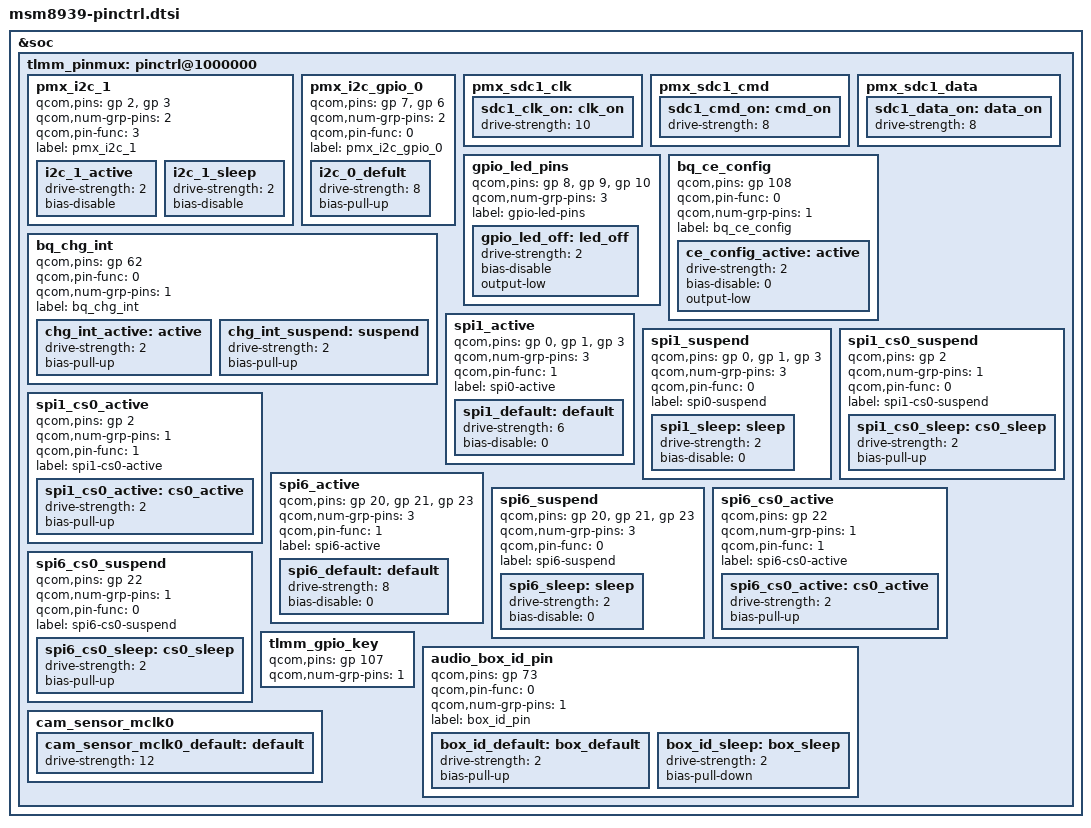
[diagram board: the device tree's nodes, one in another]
/* Copyright (c) 2014, The Linux Foundation. All rights reserved.
 *
 * This program is free software; you can redistribute it and/or modify
 * it under the terms of the GNU General Public License version 2 and
 * only version 2 as published by the Free Software Foundation.
 *
 * This program is distributed in the hope that it will be useful,
 * but WITHOUT ANY WARRANTY; without even the implied warranty of
 * MERCHANTABILITY or FITNESS FOR A PARTICULAR PURPOSE.  See the
 * GNU General Public License for more details.
 */

#include "../msm8939-pinctrl.dtsi"

&soc {
	tlmm_pinmux: pinctrl@1000000 {
		pmx_i2c_1 {
			qcom,pins = <&gp 2>, <&gp 3>; /* SDA, SCL */
			qcom,num-grp-pins = <2>;
			qcom,pin-func = <3>;
			label = "pmx_i2c_1";

			i2c_1_active: i2c_1_active {
				drive-strength = <2>;
				bias-disable;
			};

			i2c_1_sleep: i2c_1_sleep {
				drive-strength = <2>;
				bias-disable;
			};
		};

		pmx_i2c_gpio_0{
			/* CLK, DATA */
			qcom,pins = <&gp 7>, <&gp 6>;
			qcom,num-grp-pins = <2>;
			qcom,pin-func = <0>;
			label = "pmx_i2c_gpio_0";
			i2c_0_defult: i2c_0_defult {
				drive-strength = <8>; /* 8 MA */
				bias-pull-up; /* pull up */
			};
		};

		/delete-node/ sdhc2_cd_pin;

		pmx_sdc1_clk {
			sdc1_clk_on: clk_on {
				drive-strength = <10>; /* 10 MA */
			};
		};

		pmx_sdc1_cmd {
			sdc1_cmd_on: cmd_on {
				drive-strength = <8>; /* 8 MA */
			};
		};

		pmx_sdc1_data {
			sdc1_data_on: data_on {
				drive-strength = <8>; /* 8 MA */
			};
		};

		gpio_led_pins {
			qcom,pins = <&gp 8>, <&gp 9>, <&gp 10>;
			qcom,num-grp-pins = <3>;
			label = "gpio-led-pins";
			gpio_led_off: led_off {
				drive-strength = <2>;
				bias-disable;
				output-low;
			};
		};

		bq_ce_config {
			qcom,pins = <&gp 108>;
			qcom,pin-func = <0>;
			qcom,num-grp-pins = <1>;
			label = "bq_ce_config";

			ce_config_active: active {
			drive-strength = <2>; /* 2 mA */
				bias-disable = <0>; /* no pull */
				output-low;
			};
		};

		bq_chg_int {
			qcom,pins = <&gp 62>;
			qcom,pin-func = <0>;
			qcom,num-grp-pins = <1>;
			label = "bq_chg_int";

			chg_int_active: active {
				drive-strength = <2>;
				bias-pull-up;
			};

			chg_int_suspend: suspend {
				drive-strength = <2>;
				bias-pull-up;
			};
		};

		spi1_active {
			/* MOSI, MISO, CLK */
			qcom,pins = <&gp 0>, <&gp 1>, <&gp 3>;
			qcom,num-grp-pins = <3>;
			qcom,pin-func = <1>;
			label = "spi0-active";
			/* active state */
			spi1_default: default {
					drive-strength = <6>; /* 12 MA */
					bias-disable = <0>; /* No PULL */
			};
		};

		spi1_suspend {
			/* MOSI, MISO, CLK */
			qcom,pins = <&gp 0>, <&gp 1>, <&gp 3>;
			qcom,num-grp-pins = <3>;
			qcom,pin-func = <0>;
			label = "spi0-suspend";
			/* suspended state */
			spi1_sleep: sleep {
					drive-strength = <2>; /* 2 MA */
					bias-disable = <0>; /* No PULL */
			};
		};

		spi1_cs0_active {
			/* CS */
			qcom,pins = <&gp 2>;
			qcom,num-grp-pins = <1>;
			qcom,pin-func = <1>;
			label = "spi1-cs0-active";
			spi1_cs0_active: cs0_active {
				drive-strength = <2>;
				bias-pull-up;
			};
		};

		spi1_cs0_suspend {
			/* CS */
			qcom,pins = <&gp 2>;
			qcom,num-grp-pins = <1>;
			qcom,pin-func = <0>;
			label = "spi1-cs0-suspend";
			spi1_cs0_sleep: cs0_sleep {
				drive-strength = <2>;
				bias-pull-up;
			};
		};

		spi6_active {
			/* MOSI, MISO, CLK */
			qcom,pins = <&gp 20>, <&gp 21>, <&gp 23>;
			qcom,num-grp-pins = <3>;
			qcom,pin-func = <1>;
			label = "spi6-active";
			/* active state */
			spi6_default: default {
				drive-strength = <8>; /* 16 MA */
				bias-disable = <0>; /* No PULL */
			};
		};

		spi6_suspend {
			/* MOSI, MISO, CLK */
			qcom,pins = <&gp 20>, <&gp 21>, <&gp 23>;
			qcom,num-grp-pins = <3>;
			qcom,pin-func = <0>;
			label = "spi6-suspend";
			/* suspended state */
			spi6_sleep: sleep {
				drive-strength = <2>; /* 2 MA */
				bias-disable = <0>; /* No PULL */
			};
		};

		spi6_cs0_active {
			/* CS */
			qcom,pins = <&gp 22>;
			qcom,num-grp-pins = <1>;
			qcom,pin-func = <1>;
			label = "spi6-cs0-active";
			spi6_cs0_active: cs0_active {
				drive-strength = <2>;
				bias-pull-up;
			};
		};

		spi6_cs0_suspend {
			/* CS */
			qcom,pins = <&gp 22>;
			qcom,num-grp-pins = <1>;
			qcom,pin-func = <0>;
			label = "spi6-cs0-suspend";
			spi6_cs0_sleep: cs0_sleep {
				drive-strength = <2>;
				bias-pull-up;
			};
		};

		tlmm_gpio_key {
			qcom,pins = <&gp 107>;
			qcom,num-grp-pins = <1>;
		};

		audio_box_id_pin {
			qcom,pins = <&gp 73>;
			qcom,pin-func = <0>;
			qcom,num-grp-pins = <1>;
			label = "box_id_pin";
			box_id_default: box_default {
				drive-strength = <2>;
				bias-pull-up;
			};
			box_id_sleep: box_sleep {
				drive-strength = <2>;
				bias-pull-down;
			};
		};

		cam_sensor_mclk0 {
			cam_sensor_mclk0_default: default {
				drive-strength = <12>; /* 12 MA */
			};
		};
	};
};
